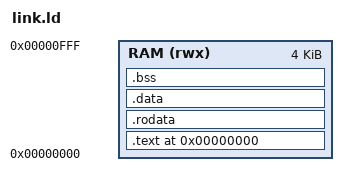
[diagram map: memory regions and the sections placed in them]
OUTPUT_ARCH(riscv)
ENTRY(_start)

MEMORY
{
    RAM (rwx) : ORIGIN = 0x00000000, LENGTH = 4K
}

SECTIONS
{
    . = ORIGIN(RAM);

    .text : ALIGN(4)
    {
        KEEP(*(.text.start))
        *(.text .text.*)
    } > RAM

    .rodata : ALIGN(4)
    {
        *(.rodata .rodata.*)
    } > RAM

    .data : ALIGN(4)
    {
        *(.data .data.*)
    } > RAM

    .bss (NOLOAD) : ALIGN(4)
    {
        __bss_start = .;
        *(.bss .bss.*)
        *(COMMON)
        __bss_end = .;
    } > RAM

    . = ALIGN(16);
    __program_end = .;
    __stack_top = ORIGIN(RAM) + LENGTH(RAM);

    /DISCARD/ :
    {
        *(.comment)
        *(.note*)
        *(.eh_frame*)
        *(.riscv.attributes)
    }

    ASSERT(__program_end <= __stack_top,
           "Firmware image exceeds the 4 KiB SoC RAM")
}
